# D1H.pdf register map
Vendor: Allwinner; Series: D1H.pdf; File version: 0.1
CPU: XuanTie C906 RISC-V CPU 0, little endian, MPU, FPU, double-precision FPU, 0 interrupt priority bits
Registers are 32-bit, read-write, reset 0x0 unless marked. A register's access mark holds for its fields unless they carry their own. Offsets are from the block's base; [hi:lo] are bit positions; lines under a group give offsets from that group; {n}, {i} and the like mark numbered series; 'fields as' and 'values as' point back to an identical list; <NAME> marks a mode.

## Audio_Codec (part 2 of 5)
Base 0x02030000
0x00 AUDIO CODEC group
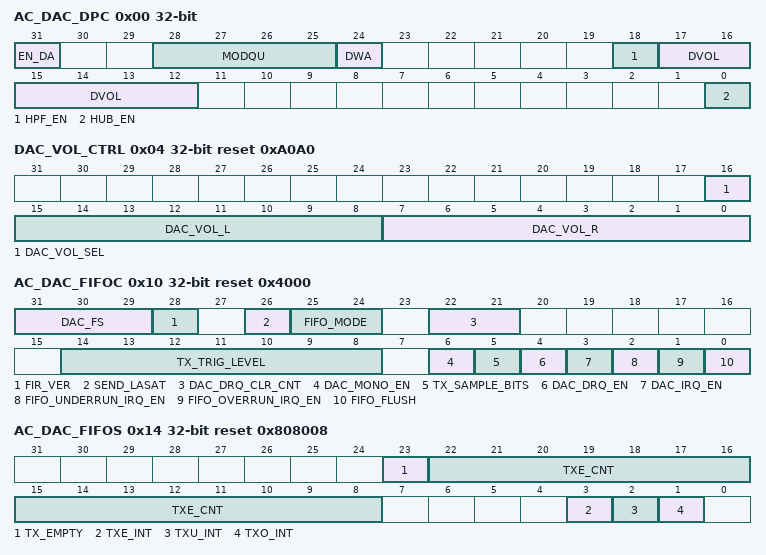
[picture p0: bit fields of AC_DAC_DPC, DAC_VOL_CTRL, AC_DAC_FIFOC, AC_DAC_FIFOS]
  0x00 AC_DAC_DPC — DAC Digital Part Control Register
    [31] EN_DA — DAC Digital Part Enable 0: Disabled 1: Enabled
      0=Disabled; 1=Enabled
    [28:25] MODQU — Internal DAC Quantization Levels Levels = [7*(21 + MODQU[3:0])]/128 Default levels = 7*21/128 = 1.15
    [24] DWA — DWA Function Disable 0: Enabled 1: Disabled
      0=Enabled; 1=Disabled
    [18] HPF_EN — High Pass Filter Enable 0: Disabled 1: Enabled
      0=Disabled; 1=Enabled
    [17:12] DVOL — Digital volume control: DVC, ATT = DVC[5:0]*(-1.16 dB) 64 steps, -1.16 dB/step
    [0] HUB_EN — Audio Hub Enable The bit takes effect only when the EN_DA is set to 1. System Domain: Audio Codec/I2S0/I2S1/I2S2/OWA TXFIFO Hub Enable. 0: Disabled 1: Enabled
      0=Disabled; 1=Enabled
  0x04 DAC_VOL_CTRL reset 0xA0A0 — DAC Volume Control Register
    [16] DAC_VOL_SEL — DAC Volume Control Selection Enable 0: Disabled 1: Enabled
      0=Disabled; 1=Enabled
    [15:8] DAC_VOL_L — DAC left channel volume (-119.25 dB to 71.25 dB, 0.75 dB/Step) 0x00: Mute 0x01: -119.25 dB ... 0x9F = -0.75 dB 0xA0 = 0 dB 0xA1 = 0.75 dB ... 0xFF = 71.25 dB
      0=Mute; 1=_minus_119_point_25_dB (-119.25 dB ... 0x9F = -0.75 dB 0xA0 = 0 dB 0xA1 = 0.75 dB ... 0xFF = 71.25 dB)
    [7:0] DAC_VOL_R — DAC right channel volume (-119.25 dB To 71.25 dB, 0.75 dB/Step) 0x00: Mute 0x01: -119.25 dB ... 0x9F = -0.75 dB 0xA0 = 0 dB 0xA1 = 0.75 dB ... 0xFF = 71.25 dB
      values as DAC_VOL_L
  0x10 AC_DAC_FIFOC reset 0x4000 — DAC FIFO Control Register
    [31:29] DAC_FS — Sample Rate of DAC 000: 48 kHz 010: 24 kHz 100: 12 kHz 110: 192 kHz 001: 32 kHz 011: 16 kHz 101: 8 kHz 111: 96 kHz 44.1 kHz/22.05 kHz/11.025 kHz can be supported by Audio PLL Configure Bit
      0=_48_kHz; 2=_24_kHz; 4=_12_kHz; 6=_192_kHz; 1=_32_kHz; 3=_16_kHz; 5=_8_kHz; 7=96 kHz 44.1 kHz/22.05 kHz/11.025 kHz can be supported by Audio PLL Configure Bit
    [28] FIR_VER — FIR Version 0: 64-Tap FIR 1: 32-Tap FIR
      0=_64_minus_Tap (64-Tap FIR); 1=_32_minus_Tap (32-Tap FIR)
    [26] SEND_LASAT — Audio sample select when TX FIFO underrun 0: Sending zero 1: Sending the last audio sample
      0=Sending_zero; 1=Sending the last audio sample
    [25:24] FIFO_MODE — For 20-bit transmitted audio sample: 00/10: FIFO_I[19:0] = {TXDATA[31:12]} 01/11: FIFO_I[19:0] = {TXDATA[19:0]} For 16-bit transmitted audio sample: 00/10: FIFO_I[19:0] = {TXDATA[31:16], 4’b0} 01/11: FIFO_I[19:0] = {TXDATA[15:0], 4’b0}
    [22:21] DAC_DRQ_CLR_CNT — When TX FIFO available room is less than or equal N, the DRQ request will be de-asserted. N is defined here: 00: IRQ/DRQ de-asserted when WLEVEL > TXTL 01: 4 10: 8 11: 16
      0=IRQ_slash_DRQ (IRQ/DRQ de-asserted when WLEVEL > TXTL); 1=_4; 2=_8; 3=_16
    [14:8] TX_TRIG_LEVEL — TX FIFO Empty Trigger Level (TXTL[12:0]) Interrupt and DMA request trigger level for TX FIFO normal condition. IRQ/DRQ generated when WLEVEL ≤ TXTL
    [6] DAC_MONO_EN — DAC Mono Enable 0: Stereo, 64 levels FIFO 1: Mono, 128 levels FIFO When enabled, L & R channel send the same data.
      0=Stereo, 64 levels FIFO; 1=Mono, 128 levels FIFO When enabled, L & R channel send the same data
    [5] TX_SAMPLE_BITS — Transmitting Audio Sample Resolution 0: 16 bits 1: 20 bits
      0=_16_bits; 1=_20_bits
    [4] DAC_DRQ_EN — DAC FIFO Empty DRQ Enable 0: Disabled 1: Enabled
      0=Disabled; 1=Enabled
    [3] DAC_IRQ_EN — DAC FIFO Empty IRQ Enable 0: Disabled 1: Enabled
      0=Disabled; 1=Enabled
    [2] FIFO_UNDERRUN_IRQ_EN — DAC FIFO Underrun IRQ Enable 0: Disabled 1: Enabled
      0=Disabled; 1=Enabled
    [1] FIFO_OVERRUN_IRQ_EN — DAC FIFO Overrun IRQ Enable 0: Disabled 1: Enabled
      0=Disabled; 1=Enabled
    [0] FIFO_FLUSH write-clears — DAC FIFO Flush Write ‘1’ to flush TX FIFO, self clear to ‘0’
  0x14 AC_DAC_FIFOS reset 0x808008 — DAC FIFO Status Register
    [23] TX_EMPTY ro — TX FIFO Empty 0: No room for new sample in TX FIFO 1: More than one room for new sample in TX FIFO (>= 1 word)
      0=No room for new sample in TX FIFO; 1=More than one room for new sample in TX FIFO (>= 1 word)
    [22:8] TXE_CNT ro — TX FIFO Empty Space Word Counter
    [3] TXE_INT write-1-clears — TX FIFO Empty Pending Interrupt 0: No Pending IRQ 1: FIFO Empty Pending Interrupt Write ‘1’ to clear this interrupt or automatically clear if the interrupt condition fails.
      0=No Pending IRQ; 1=FIFO (FIFO Empty Pending Interrupt Write ‘1’ to clear this interrupt or automatically clear if the interrupt condition fails.)
    [2] TXU_INT write-1-clears — TX FIFO Underrun Pending Interrupt 0: No Pending Interrupt 1: FIFO Underrun Pending Interrupt Write ‘1’ to clear this interrupt
      0=No Pending Interrupt; 1=FIFO (FIFO Underrun Pending Interrupt Write ‘1’ to clear this interrupt)
    [1] TXO_INT write-1-clears — TX FIFO Overrun Pending Interrupt 0: No Pending Interrupt 1: FIFO Overrun Pending Interrupt Write ‘1’ to clear this interrupt
      0=No Pending Interrupt; 1=FIFO (FIFO Overrun Pending Interrupt Write ‘1’ to clear this interrupt)
  0x20 AC_DAC_TXDATA — DAC TX DATA Register
    [31:0] TX_DATA wo — Write the transmitting left and right channel sample data to this register one by one. Write the left channel sample data first and then the right channel sample.
  0x24 AC_DAC_CNT — DAC TX FIFO Counter Register
    [31:0] TX_CNT — TX Sample Counter The audio sample number of sending into TXFIFO. When one sample is put into TXFIFO by DMA or by host IO, the TX sample counter register increases by one. The TX sample counter register can be set to any initial valve at any time. After being updated by the initial value, the counter register should count from this initial value.
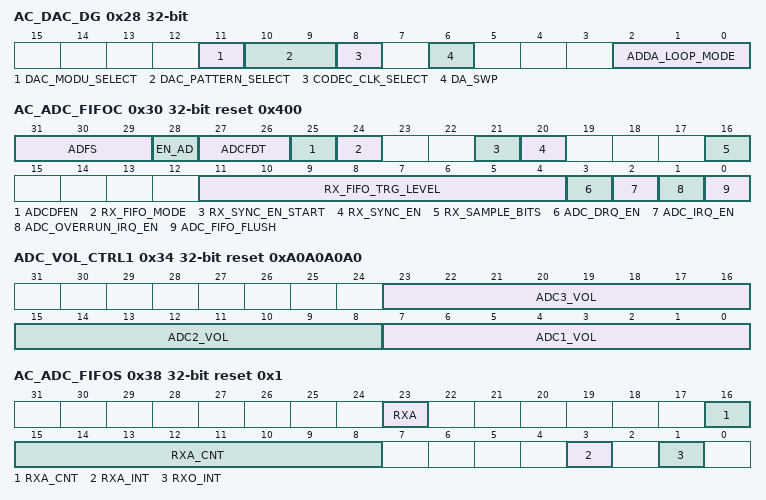
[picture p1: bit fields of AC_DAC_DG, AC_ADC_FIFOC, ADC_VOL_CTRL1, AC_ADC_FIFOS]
  0x28 AC_DAC_DG — DAC Debug Register
    [11] DAC_MODU_SELECT — DAC Modulator Debug 0: DAC Modulator Normal Mode 1: DAC Modulator Debug Mode
      0=DAC Modulator Normal Mode; 1=DAC Modulator Debug Mode
    [10:9] DAC_PATTERN_SELECT — DAC Pattern Select 00: Normal (Audio sample from TX FIFO) 01: -6 dB Sin wave 10: -60 dB Sin wave 11: Silent wave
      0=Normal (Audio sample from TX FIFO); 1=_minus_6_dB (-6 dB Sin wave); 2=_minus_60_dB (-60 dB Sin wave); 3=Silent wave
    [8] CODEC_CLK_SELECT — CODEC Clock Source Select 0: CODEC clock from PLL 1: CODEC clock from OSC (for Debug)
      0=CODEC_clock_from_PLL; 1=CODEC clock from OSC (for Debug)
    [6] DA_SWP — DAC Output Channel Swap Enable 0: Disabled 1: Enabled
      0=Disabled; 1=Enabled
    [2:0] ADDA_LOOP_MODE — ADDA Loop Mode Select 000: Disabled 001: ADDA LOOP MODE DACL/DACR is connected to ADC1/ADC2 010: ADDA LOOP MODE DACL/DACR is connected to ADC3 Others: Reserved
  0x30 AC_ADC_FIFOC reset 0x400 — ADC FIFO Control Register
    [31:29] ADFS — Sample Rate of ADC 000: 48 kHz 010: 24 kHz 100: 12 kHz 110: Reserved 001: 32 kHz 011: 16 kHz 101: 8 kHz 111: Reserved 44.1 kHz/22.05 kHz/11.025 kHz can be supported by Audio PLL Configure Bit.
      0=_48_kHz; 2=_24_kHz; 4=_12_kHz; 1=_32_kHz; 3=_16_kHz; 5=_8_kHz
    [28] EN_AD — ADC Digital Part Enable 0: Disabled 1: Enabled
      0=Disabled; 1=Enabled
    [27:26] ADCFDT — ADC FIFO delay time for writing data after EN_AD 00: 5 ms 01: 10 ms 10: 20 ms 11: 30 ms
      0=_5_ms; 1=_10_ms; 2=_20_ms; 3=_30_ms
    [25] ADCDFEN — ADC FIFO delay function for writing data after EN_AD 0: Disabled 1: Enabled
      0=Disabled; 1=Enabled
    [24] RX_FIFO_MODE — RX FIFO Output Mode (Mode 0, 1) 0: Expanding ‘0’ at LSB of TX FIFO register 1: Expanding received sample sign bit at MSB of TX FIFO register For 20-bit received audio sample: Mode 0: RXDATA[31:0] = {FIFO_O[19:0], 12’h0} Mode 1: RXDATA[31:0] = {12{FIFO_O[19]}, FIFO_O[19:0]} For 16-bit received audio sample: Mode 0: RXDATA[31:0] = {FIFO_O[19:4], 16’h0} Mode 1: RXDATA[31:0] = {16{FIFO_O[19]}, FIFO_O[19:4]}
      0=Expanding__quote_0_quote_ (Expanding ‘0’ at LSB of TX FIFO register); 1=Expanding received sample sign bit at MSB of TX FIFO register For 20-bit received audio sample: Mode 0: RXDATA[31:0] = {FIFO_O[19:0], 12’h0} Mode 1: RXDATA[31:0] = {12{FIFO_O[19]}, FIFO_O[19:0]} For 16-bit received audio sample: Mode 0: RXDATA[31:0] = {FIFO_O[19:4], 16’h0} Mode 1: RXDATA[31:0] = {16{FIFO_O[19]}, FIFO_O[19:4]}
    [21] RX_SYNC_EN_START — The bit takes effect only when RX_SYNC_EN is set to 1. System Domain: Audio codec/I2S0/I2S1/I2S2/DMIC Synchronize Enable Start. 0: Disabled 1: Enabled
      0=Disabled; 1=Enabled
    [20] RX_SYNC_EN — Audiocodec RX Synchronize Enable 0: Disabled 1: Enabled
      0=Disabled; 1=Enabled
    [16] RX_SAMPLE_BITS — Receiving Audio Sample Resolution 0: 16 bits 1: 20 bits
      0=_16_bits; 1=_20_bits
    [11:4] RX_FIFO_TRG_LEVEL — RX FIFO Trigger Level (RXTL[5:0]) Interrupt and DMA request trigger level for RX FIFO normal condition IRQ/DRQ generated when WLEVEL > RXTL[5:0]
    [3] ADC_DRQ_EN — ADC FIFO Data Available DRQ Enable 0: Disabled 1: Enabled
      0=Disabled; 1=Enabled
    [2] ADC_IRQ_EN — ADC FIFO Data Available IRQ Enable 0: Disabled 1: Enabled
      0=Disabled; 1=Enabled
    [1] ADC_OVERRUN_IRQ_EN — ADC FIFO Overrun IRQ Enable 0: Disabled 1: Enabled
      0=Disabled; 1=Enabled
    [0] ADC_FIFO_FLUSH write-clears — ADC FIFO Flush Write ‘1’ to flush TX FIFO, self clear to ‘0’.
  0x34 ADC_VOL_CTRL1 reset 0xA0A0A0A0 — ADC Volume Control1 Register
    [all] fields
      0=Mute; 1=_minus_119_point_25_dB (-119.25 dB ...); 159=_minus_0_point_75_dB (-0.75 dB); 160=_0_dB; 161=_0_point_75_dB (0.75 dB ...); 255=_71_point_25_dB (71.25 dB)
    [23:16] ADC3_VOL — ADC3 channel volume (-119.25 dB To 71.25 dB, 0.75 dB/Step) 0x00: Mute 0x01: -119.25 dB ... 0x9F: -0.75 dB 0xA0: 0 dB 0xA1: 0.75 dB ... 0xFF: 71.25 dB
    [15:8] ADC2_VOL — ADC2 channel volume (-119.25 dB To 71.25 dB, 0.75 dB/Step) 0x00: Mute 0x01: -119.25 dB ... 0x9F: -0.75 dB 0xA0: 0 dB 0xA1: 0.75 dB ... 0xFF: 71.25 dB
    [7:0] ADC1_VOL — ADC1 channel volume (-119.25 dB To 71.25 dB, 0.75 dB/Step) 0x00: Mute 0x01: -119.25 dB ... 0x9F: -0.75 dB 0xA0: 0 dB 0xA1: 0.75 dB ... 0xFF: 71.25 dB
  0x38 AC_ADC_FIFOS reset 0x1 — ADC FIFO Status Register
    [23] RXA ro — RX FIFO Available 0: No available data in RX FIFO 1: More than one sample in RX FIFO (>= 1 word)
      0=No available data in RX FIFO; 1=More than one sample in RX FIFO (>= 1 word)
    [16:8] RXA_CNT ro — RX FIFO Available Sample Word Counter
    [3] RXA_INT write-1-clears — RX FIFO Data Available Pending Interrupt 0: No Pending IRQ 1: Data Available Pending IRQ Write ‘1’ to clear this interrupt or automatic clear if the interrupt condition fails.
      0=No Pending IRQ; 1=Data Available Pending IRQ Write ‘1’ to clear this interrupt or automatic clear if the interrupt condition fails
    [1] RXO_INT write-1-clears — RX FIFO Overrun Pending Interrupt 0: No Pending IRQ 1: FIFO Overrun Pending IRQ Write ‘1’ to clear this interrupt.
      0=No Pending IRQ; 1=FIFO (FIFO Overrun Pending IRQ Write ‘1’ to clear this interrupt.)
  0x40 AC_ADC_RXDATA — ADC RX Data Register
    [31:0] RX_DATA ro — RX Sample The host can get one sample by reading this register. The left channel sample data comes first and then the right channel sample.
  0x44 AC_ADC_CNT — ADC RX Counter Register
    [31:0] RX_CNT — RX Sample Counter The audio sample number of writing into RXFIFO. When one sample is written by Digital Audio Engine, the RX sample counter register increases by one. The RX sample counter register can be set to any initial valve at any time. After being updated by the initial value, the counter register should count from this initial value.
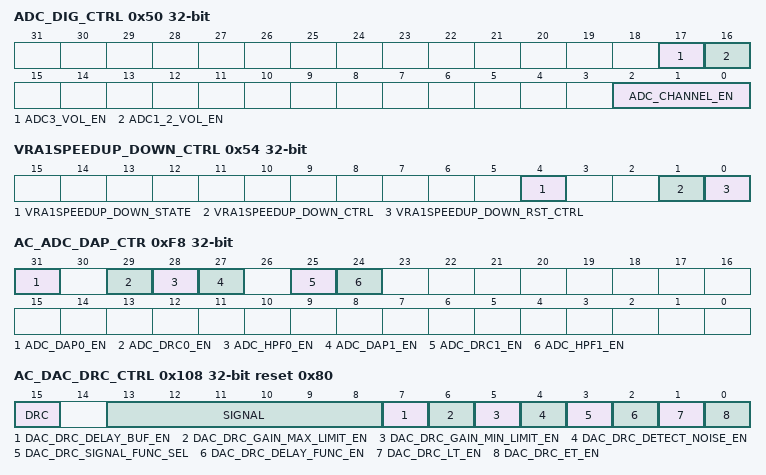
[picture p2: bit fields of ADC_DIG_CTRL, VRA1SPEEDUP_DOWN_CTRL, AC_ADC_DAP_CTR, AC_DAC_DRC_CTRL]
  0x50 ADC_DIG_CTRL — ADC Digtial Control Register
    [17] ADC3_VOL_EN — ADC3 Volume Control Enable 0: Disabled 1: Enabled
      0=Disabled; 1=Enabled
    [16] ADC1_2_VOL_EN — ADC1/2 Volume Control Enable 0: Disabled 1: Enabled
      0=Disabled; 1=Enabled
    [2:0] ADC_CHANNEL_EN — Bit 3: ADC4 enabled Bit 2: ADC3 enabled Bit 1: ADC2 enabled Bit 0: ADC1 enabled
  0x54 VRA1SPEEDUP_DOWN_CTRL
    [4] VRA1SPEEDUP_DOWN_STATE ro — Only if VAR1SPEEDUP_DOWN_Further_CTRL (0x310[22]) is set 0, VAR1Speedup Down State is valid. 0: VAR1Speedup_Down does not work. 1: VAR1Speedup_Down works.
      0=VAR1Speedup_Down does not work; 1=VAR1Speedup_Down_works
    [1] VRA1SPEEDUP_DOWN_CTRL — VAR1Speedup Down Manual Control Enable 0: Disabled. VAR1Speedup Down converts to 1 after the bus rst releases 32 ms. 1: Enabled. VAR1Speedup Down converts to 1 immediately.
      0=Disabled. VAR1Speedup Down converts to 1 after the bus rst releases 32 ms.; 1=Enabled. VAR1Speedup Down converts to 1 immediately.
    [0] VRA1SPEEDUP_DOWN_RST_CTRL — VAR1Speedup Down RST Manual Control Enable 0: Disabled. VAR1Speedup Down converts to 1 after the bus rst releases 32 ms. 1: Enabled. VAR1Speedup Down reset 0 immediately.
      0=Disabled. VAR1Speedup Down converts to 1 after the bus rst releases 32 ms.; 1=Enabled. VAR1Speedup Down reset 0 immediately.
  0xF8 AC_ADC_DAP_CTR — ADC DAP Control Register
    [31] ADC_DAP0_EN — (control the DAP of ADC1/2) DAP for ADC enable 0: Bypassed 1: Enabled
      0=Bypassed; 1=Enabled
    [29] ADC_DRC0_EN — ADC DRC0 enable control 0: Disabled 1: Enabled
      0=Disabled; 1=Enabled
    [28] ADC_HPF0_EN — ADC HPF0 enable control 0: Disabled 1: Enabled
      0=Disabled; 1=Enabled
    [27] ADC_DAP1_EN — (control the DAP of ADC3) ADC DAP1 enable control
    [25] ADC_DRC1_EN — ADC DRC1 enable control 0: Disabled 1: Enabled
      0=Disabled; 1=Enabled
    [24] ADC_HPF1_EN — ADC HPF1 enable control 0: Disabled 1: Enabled
      0=Disabled; 1=Enabled
  0x100 AC_DAC_DRC_HHPFC reset 0xFF — DAC DRC High HPF Coef Register
    [10:0] HPF — coefficient setting and the data is 3.24 format.
  0x104 AC_DAC_DRC_LHPFC reset 0xFAC1 — DAC DRC Low HPF Coef Register
    [15:0] HPF — coefficient setting and the data is 3.24 format.
  0x108 AC_DAC_DRC_CTRL reset 0x80 — DAC DRC Control Register
    [15] DRC ro — delay buffer data output state when The DRC delay function is enabled and the DRC function is disabled. After disabling the DRC function and this bit goes to 0, write the DRC delay function bit to 0. 0: Not completed 1: Completed
      0=Not_completed; 1=Completed
    [13:8] SIGNAL — Signal delay time setting 6'h00: (8x1) fs 6'h01: (8x2) fs 6'h02: (8x3) fs ---------------------------------------- 6'h2e: (8*47) fs 6'h2f: (8*48) fs 6'h30 -- 6'h3f: (8*48) fs Delay time = 8*(n + 1) fs, n<6'h30; When the delay function is disabled, the signal delay time is unused.
    [7] DAC_DRC_DELAY_BUF_EN — The delay buffer use or not when the DRC is disabled and the DRC buffer data output completely. 0: Do not use the buffer. 1: Use the buffer.
      0=Do_not_use_the_buffer; 1=Use_the_buffer
    [6] DAC_DRC_GAIN_MAX_LIMIT_EN — DRC gain max limit enable 0: Disabled 1: Enabled
      0=Disabled; 1=Enabled
    [5] DAC_DRC_GAIN_MIN_LIMIT_EN — DRC gain min limit enable When this function is enabled, it will overwrite the noise detect function. 0: Disabled 1: Enabled
      0=Disabled; 1=Enabled
    [4] DAC_DRC_DETECT_NOISE_EN — Control the DRC to detect noise when ET is enabled. 0: Disabled 1: Enabled
      0=Disabled; 1=Enabled
    [3] DAC_DRC_SIGNAL_FUNC_SEL — Signal function select 0: RMS filter 1: Peak filter When the signal function selects the Peak filter, the RMS parameter is unused. (AC_DRC_LRMSHAT, AC_DRC_LRMSLAT, AC_DRC_LRMSHAT, AC_DRC_LRMSLAT) When the signal function selects the RMS filter, the Peak filter parameter is unused. (AC_DRC_LPFHAT, AC_DRC_LPFLAT, AC_DRC_RPFHAT, AC_DRC_RPFLAT, AC_DRC_LPFHRT, AC_DRC_LPFLRT, AC_DRC_RPFHRT, and AC_DRC_RPFLRT)
      0=RMS (RMS filter); 1=Peak filter When the signal function selects the Peak filter, the RMS parameter is unused. (AC_DRC_LRMSHAT, AC_DRC_LRMSLAT, AC_DRC_LRMSHAT, AC_DRC_LRMSLAT) When the signal function selects the RMS filter, the Peak filter parameter is unused. (AC_DRC_LPFHAT, AC_DRC_LPFLAT, AC_DRC_RPFHAT, AC_DRC_RPFLAT, AC_DRC_LPFHRT, AC_DRC_LPFLRT, AC_DRC_RPFHRT, and AC_DRC_RPFLRT)
    [2] DAC_DRC_DELAY_FUNC_EN — Delay function enable 0: Disabled 1: Enabled When the bit is disabled, the signal delay time is unused.
      0=Disabled; 1=Enabled When the bit is disabled, the signal delay time is unused
    [1] DAC_DRC_LT_EN — DRC LT enable 0: Disabled 1: Enabled When the bit is disabled, Kl and OPL parameter is unused.
      0=Disabled; 1=Enabled When the bit is disabled, Kl and OPL parameter is unused
    [0] DAC_DRC_ET_EN — DRC ET enable 0: Disabled 1: Enabled When the bit is disabled, Ke and OPE parameter is unused.
      0=Disabled; 1=Enabled When the bit is disabled, Ke and OPE parameter is unused
  0x10C AC_DAC_DRC_LPFHAT reset 0xB — DAC DRC Left Peak Filter High Attack Time Coef Register
    [10:0] DAC_DRC_LPFHAT — The left peak filter attack time parameter setting, which is determined by the equation that AT = 1-exp (-2.2Ts/ta). The format is 3.24. (The default value is 1 ms)
  0x110 AC_DAC_DRC_LPFLAT reset 0x77BF — DAC DRC Left Peak Filter Low Attack Time Coef Register
    [15:0] DAC_DRC_LPFLAT — The left peak filter attack time parameter setting, which is determined by the equation that AT = 1-exp (-2.2Ts/ta). The format is 3.24. (The default value is 1 ms)
  0x114 AC_DAC_DRC_RPFHAT reset 0xB — DAC DRC Right Peak Filter High Attack Time Coef Register
    [15:0] DAC_DRC_RPFHAT — The right peak filter attack time parameter setting, which is determined by the equation that AT = 1-exp (-2.2Ts/ta). The format is 3.24. (The default value is 1 ms)
  0x118 AC_DAC_DRC_RPFLAT reset 0x77BF — DAC DRC Peak Filter Low Attack Time Coef Register
    [15:0] DAC_DRC_RPFLAT — The left peak filter attack time parameter setting, which is determined by the equation that AT = 1-exp (-2.2Ts/ta). The format is 3.24. (The default value is 1 ms)
  0x11C AC_DAC_DRC_LPFHRT reset 0xFF — DAC DRC Left Peak Filter High Release Time Coef Register
    [10:0] DAC_DRC_LPFHRT — The left peak filter release time parameter setting, which is determined by the equation that RT = exp (-2.2Ts/tr). The format is 3.24. (The default value is 100 ms)
  0x120 AC_DAC_DRC_LPFLRT reset 0xE1F8 — DAC DRC Left Peak Filter Low Release Time Coef Register
    [15:0] DAC_DRC_LPFLRT — The left peak filter release time parameter setting, which is determined by the equation that RT = exp (-2.2Ts/tr). The format is 3.24. (The default value is 100 ms)
  0x124 AC_DAC_DRC_RPFHRT reset 0xFF — DAC DRC Right Peak filter High Release Time Coef Register
    [15:0] DAC_DRC_RPFHRT — The right peak filter release time parameter setting, which is determined by the equation that RT = exp (-2.2Ts/tr). The format is 3.24. (The default value is 100 ms)
  0x128 AC_DAC_DRC_RPFLRT reset 0xE1F8 — DAC DRC Right Peak filter Low Release Time Coef Register
    [15:0] DAC_DRC_RPFLRT — The right peak filter release time parameter setting, which is determined by the equation that AT = exp(-2.2Ts/tr). The format is 3.24. (The default value is 100 ms)
  0x12C AC_DAC_DRC_LRMSHAT reset 0x1 — DAC DRC Left RMS Filter High Coef Register
    [10:0] DAC_DRC_LRMSHAT — The left RMS filter average time parameter setting, which is determined by the equation that AT = 1-exp (-2.2Ts/tav). The format is 3.24. (The default value is 10 ms)
  0x130 AC_DAC_DRC_LRMSLAT reset 0x2BAF — DAC DRC Left RMS Filter Low Coef Register
    [15:0] DAC_DRC_LRMSLAT — The left RMS filter average time parameter setting, which is determined by the equation that AT = 1-exp (-2.2Ts/tav). The format is 3.24. (The default value is 10 ms)
  0x134 AC_DAC_DRC_RRMSHAT reset 0x2BAF — DAC DRC Right RMS Filter High Coef Register
    [15:0] DAC_DRC_RRMSHAT — The right RMS filter average time parameter setting, which is determined by the equation that AT = 1-exp (-2.2Ts/tav). The format is 3.24. (The default value is 10 ms)
  0x138 AC_DAC_DRC_RRMSLAT reset 0x2BAF — DAC DRC Right RMS Filter Low Coef Register
    [15:0] DAC_DRC_RRMSLAT — The right RMS filter average time parameter setting, which is determined by the equation that AT = 1-exp (-2.2Ts/tav). The format is 3.24. (The default value is 10 ms)
  0x13C AC_DAC_DRC_HCT reset 0x6A4 — DAC DRC Compressor Threshold High Setting Register
    [15:0] DAC_DRC_HCT — The compressor threshold setting, which is set by the equation that CTin = -CT/6.0206. The format is 8.24. (The default value is - 40 dB)
  0x140 AC_DAC_DRC_LCT reset 0xD3C0 — DAC DRC Compressor Slope High Setting Register
    [15:0] DAC_DRC_LCT — The compressor threshold setting, which is set by the equation that CTin = -CT/6.0206. The format is 8.24. (The default value is - 40 dB)
  0x144 AC_DAC_DRC_HKC reset 0x80 — DAC DRC Compressor Slope High Setting Register
    [15:0] DAC_DRC_HKC — The slope of the compressor, which is determined by the equation that Kc = 1/R. R is the ratio of the compressor, which is always an integer. The format is 8.24. (The default value is 2:1)
  0x148 AC_DAC_DRC_LKC — DAC DRC Compressor Slope Low Setting Register
    [15:0] DAC_DRC_LKC — The slope of the compressor, which is determined by the equation that Kc = 1/R. R is the ratio of the compressor, which is always an integer. The format is 8.24. (The default value is 2:1)
  0x14C AC_DAC_DRC_HOPC reset 0xF95B — DAC DRC Compressor High Output at Compressor Threshold Register
    [15:0] DAC_DRC_HOPC — The output of the compressor, which is determined by the equation -OPC/6.0206. The format is 8.24 (The default value is -40 dB)
  0x150 AC_DAC_DRC_LOPC reset 0x2C3F — DAC DRC Compressor Low Output at Compressor Threshold Register
    [15:0] DAC_DRC_LOPC — The output of the compressor, which is determined by the equation OPC/6.0206. The format is 8.24. (The default value is -40 dB)
  0x154 AC_DAC_DRC_HLT reset 0x1A9 — DAC DRC Limiter Threshold High Setting Register
    [15:0] DAC_DRC_HLT — The limiter threshold setting, which is set by the equation that LTin = -LT/6.0206, The format is 8.24. (The default value is -10 dB)
  0x158 AC_DAC_DRC_LLT reset 0x34F0 — DAC DRC Limiter Threshold Low Setting Register
    [15:0] DAC_DRC_LLT — The limiter threshold setting, which is set by the equation that LTin = -LT/6.0206. The format is 8.24. (The default value is -10 dB)
  0x15C AC_DAC_DRC_HKl reset 0x5 — DAC DRC Limiter Slope High Setting Register
    [15:0] DAC_DRC_HKL — The slope of the limiter which is determined by the equation that Kl = 1/R. R is the ratio of the limiter, which is always an integer. The format is 8.24. (The default value is <50:1>)
  0x160 AC_DAC_DRC_LKl reset 0x1EB8 — DAC DRC Limiter Slope Low Setting Register
    [15:0] DAC_DRC_LKL — The slope of the limiter, which is determined by the equation that Kl = 1/R. R is the ratio of the limiter, which is always an integer. The format is 8.24. (The default value is <50:1>)
  0x164 AC_DAC_DRC_HOPL reset 0xFBD8 — DAC DRC Limiter High Output at Limiter Threshold
    [15:0] DAC_DRC_HOPL — The output of the limiter, which is determined by equation OPT/6.0206. The format is 8.24. (The default value is -25 dB)
  0x168 AC_DAC_DRC_LOPL reset 0xFBA7 — DAC DRC Limiter Low Output at Limiter Threshold
    [15:0] DAC_DRC_LOPL — The output of the limiter, which is determined by equation OPT/6.0206. The format is 8.24. (The default value is -25 dB)
  0x16C AC_DAC_DRC_HET reset 0xBA0 — DAC DRC Expander Threshold High Setting Register
    [15:0] DAC_DRC_HET — The expander threshold setting, which is set by the equation that ETin = -ET/6.0206. The format is 8.24. (The default value is -70 dB)
  0x170 AC_DAC_DRC_LET reset 0x7291 — DAC DRC Expander Threshold Low Setting Register
    [15:0] DAC_DRC_LET — The expander threshold setting, which is set by the equation that ETin = -ET/6.0206. The format is 8.24. (The default value is -70 dB)
  0x174 AC_DAC_DRC_HKE reset 0x500 — DAC DRC Expander Slope High Setting Register
    [13:0] DAC_DRC_HKE — The slope of the expander, which is determined by the equation that Ke = 1/R. R is the ratio of the expander, which is always an integer and the ke must larger than 50. The format is 8.24. (The default value is <1:5>)
  0x178 AC_DAC_DRC_LKE — DAC DRC Expander Slope Low Setting Register
    [15:0] DAC_DRC_LKE — The slope of the expander, which is determined by the equation that Ke = 1/R. R is the ratio of the expander, which is always an integer and the ke must larger than 50. The format is 8.24. (The default value is <1:5>)
  0x17C AC_DAC_DRC_HOPE reset 0xF45F — DAC DRC Expander High Output at Expander Threshold
    [15:0] DAC_DRC_HOPE — The output of the expander, which is determined by equation OPE/6.0206. The format is 8.24. (The default value is -70 dB)
  0x180 AC_DAC_DRC_LOPE reset 0x8D6E — DAC DRC Expander Low Output at Expander Threshold
    [15:0] DAC_DRC_LOPE — The output of the expander which is determined by equation OPE/6.0206. The format is 8.24. (The default value is -70 dB)
  0x184 AC_DAC_DRC_HKN reset 0x100 — DAC DRC Linear Slope High Setting Register
    [15:0] DAC_DRC_HKN — The slope of the linear, which is determined by the equation that Kn = 1/R. R is the ratio of the linear, which is always an integer. The format is 8.24. (The default value is <1:1>)
  0x188 AC_DAC_DRC_LKN — DAC DRC Linear Slope Low Setting Register
    [15:0] DAC_DRC_LKN — The slope of the linear, which is determined by the equation that Kn = 1/R. R is the ratio of the linear, which is always an integer. The format is 8.24. (The default value is <1:1>)
  0x18C AC_DAC_DRC_SFHAT reset 0x2 — DAC DRC Smooth filter Gain High Attack Time Coef Register
    [10:0] DAC_DRC_SFHAT — The smooth filter attack time parameter setting, which is determined by the equation that AT = 1-exp (-2.2Ts/tr). The format is 3.24. (The default value is 5 ms)
  0x190 AC_DAC_DRC_SFLAT reset 0x5600 — DAC DRC Smooth filter Gain Low Attack Time Coef Register
    [15:0] DAC_DRC_SFLAT — The smooth filter attack time parameter setting, which is determined by the equation that AT = 1-exp (-2.2Ts/tr). The format is 3.24. (The default value is 5 ms)
  0x194 AC_DAC_DRC_SFHRT — DAC DRC Smooth filter Gain High Release Time Coef Register
    [10:0] DAC_DRC_SFHRT — The gain smooth filter release time parameter setting, which is determined by the equation that RT = 1-exp (-2.2Ts/tr). The format is 3.24. (The default value is 200 ms)
  0x198 AC_DAC_DRC_SFLRT reset 0xF04 — DAC DRC Smooth filter Gain Low Release Time Coef Register
    [15:0] DAC_DRC_SFLRT — The gain smooth filter release time parameter setting, which is determined by the equation that RT = 1-exp (-2.2Ts/tr). The format is 3.24. (The default value is 200 ms)
  0x19C AC_DAC_DRC_MXGHS reset 0xFE56 — DAC DRC MAX Gain High Setting Register
    [15:0] DAC_DRC_MXGHS — The max gain setting, which is determined by equation MXG =MXG/6.0206. The format is 8.24 and must -20 dB < MXG < 30 dB (The default value is -10 dB)
  0x1A0 AC_DAC_DRC_MXGLS reset 0xCB0F — DAC DRC MAX Gain Low Setting Register
    [15:0] DAC_DRC_MXGLS — The max gain setting, which is determined by equation MXG =MXG/6.0206. The format is 8.24 and must -20 dB < MXG < 30 dB (The default value is -10 dB)
  0x1A4 AC_DAC_DRC_MNGHS reset 0xF95B — DAC DRC MIN Gain High Setting Register
    [15:0] DAC_DRC_MNGHS — The min gain setting, which is determined by equation MXG =MXG/6.0206. The format is 8.24 and must -60 dB ≤ MNG ≤ -40 dB (The default value is -40 dB)
  0x1A8 AC_DAC_DRC_MNGLS reset 0x2C3F — DAC DRC MIN Gain Low Setting Register
    [15:0] DAC_DRC_MNGLS — The min gain setting, which is determined by equation MXG =MNG/6.0206. The format is 8.24 and must -60 dB ≤ MNG ≤ -40 dB (The default value is -40 dB)
  0x1AC AC_DAC_DRC_EPSHC — DAC DRC Expander Smooth Time High Coef Register
    [10:0] DAC_DRC_EPSHC — The gain smooth filter release and attack time parameter setting in expander region, which are determined by the equation that RT = 1-exp (-2.2Ts/tr). The format is 3.24. (The default value is 30 ms)
  0x1B0 AC_DAC_DRC_EPSLC reset 0x640C — DAC DRC Expander Smooth Time Low Coef Register
    [15:0] DAC_DRC_EPSLC — The gain smooth filter release and attack time parameter setting in expander region, which are determined by the equation that RT = 1-exp (-2.2Ts/tr). The format is 3.24. (The default value is 30 ms)
  0x1B8 AC_DAC_DRC_HPFHGAIN reset 0x100 — DAC DRC HPF Gain High Coef Register
    [10:0] DAC_DRC_HPFHGAIN — The gain of HPF coefficient. The format is 3.24. (gain = 1)
  0x1BC AC_DAC_DRC_HPFLGAIN — DAC DRC HPF Gain Low Coef Register
    [15:0] DAC_DRC_HPFLGAIN — The gain of HPF coefficient. The format is 3.24. (gain = 1)
  0x200 AC_ADC_DRC_HHPFC reset 0xFF — ADC DRC High HPF Coef Register
    [10:0] ADC_DRC_HHPFC — HPF coefficient setting and the data is 3.24 format.
  0x204 AC_ADC_DRC_LHPFC reset 0xFAC1 — ADC DRC Low HPF Coef Register
    [15:0] HPF — coefficient setting and the data is 3.24 format.
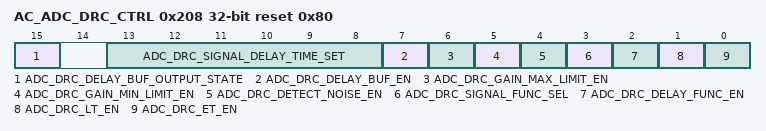
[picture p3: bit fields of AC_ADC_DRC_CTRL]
  0x208 AC_ADC_DRC_CTRL reset 0x80 — ADC DRC Control Register
    [15] ADC_DRC_DELAY_BUF_OUTPUT_STATE ro — DRC delay buffer data output state when The DRC delay function is enabled and the DRC function is disabled. After disabled DRC function and this bit goes to 0, the user should write the DRC delay function bit to 0. 0: Not completed 1: Completed
      0=Not_completed; 1=Completed
    [13:8] ADC_DRC_SIGNAL_DELAY_TIME_SET — Signal delay time setting 6'h00: (8x1) fs 6'h01: (8x2) fs 6'h02: (8x3) fs ---------------------------------------- 6'h2e: (8*47) fs 6'h2f: (8*48) fs 6'h30 -- 6'h3f: (8*48) fs Delay time = 8*(n + 1) fs, n < 6'h30; When the delay function is disabled, the signal delay time is unused.
    [7] ADC_DRC_DELAY_BUF_EN — The delay buffer use or not when the DRC is disabled and the DRC buffer data output completely. 0: Do not use the buffer 1: Use the buffer
      0=Do_not_use_the_buffer; 1=Use_the_buffer
    [6] ADC_DRC_GAIN_MAX_LIMIT_EN — DRC gain max limit enable 0: Disabled 1: Enabled
      0=Disabled; 1=Enabled
    [5] ADC_DRC_GAIN_MIN_LIMIT_EN — DRC gain min limit enable When this fuction is enabled, it will overwrite the noise detect function. 0: Disabled 1: Enabled
      0=Disabled; 1=Enabled
    [4] ADC_DRC_DETECT_NOISE_EN — Control the DRC to detect noise when ET is enabled 0: Disabled 1: Enabled
      0=Disabled; 1=Enabled
    [3] ADC_DRC_SIGNAL_FUNC_SEL — Signal function select 0: RMS filter 1: Peak filter When the signal function selects the Peak filter, the RMS parameter is unused. (AC_DRC_LRMSHAT, AC_DRC_LRMSLAT, AC_DRC_LRMSHAT, and AC_DRC_LRMSLAT) When the signal function selects the RMS filter, the Peak filter parameter is unused. (AC_DRC_LPFHAT, AC_DRC_LPFLAT, AC_DRC_RPFHAT, AC_DRC_RPFLAT, AC_DRC_LPFHRT, AC_DRC_LPFLRT, AC_DRC_RPFHRT, and AC_DRC_RPFLRT)
      0=RMS (RMS filter); 1=Peak filter When the signal function selects the Peak filter, the RMS parameter is unused. (AC_DRC_LRMSHAT, AC_DRC_LRMSLAT, AC_DRC_LRMSHAT, and AC_DRC_LRMSLAT) When the signal function selects the RMS filter, the Peak filter parameter is unused. (AC_DRC_LPFHAT, AC_DRC_LPFLAT, AC_DRC_RPFHAT, AC_DRC_RPFLAT, AC_DRC_LPFHRT, AC_DRC_LPFLRT, AC_DRC_RPFHRT, and AC_DRC_RPFLRT)
    [2] ADC_DRC_DELAY_FUNC_EN — Delay function enable 0: Disabled 1: Enabled When the bit is disabled, the signal delay time is unused.
      values as AUDIO.AC_DAC_DRC_CTRL.DAC_DRC_DELAY_FUNC_EN
    [1] ADC_DRC_LT_EN — DRC LT enable 0: Disabled 1: Enabled When the bit is disabled, Kl and OPL parameter is unused.
      values as AUDIO.AC_DAC_DRC_CTRL.DAC_DRC_LT_EN
    [0] ADC_DRC_ET_EN — DRC ET enable 0: Disabled 1: Enabled When the bit is disabled, Ke and OPE parameter is unused.
      values as AUDIO.AC_DAC_DRC_CTRL.DAC_DRC_ET_EN
  0x20C AC_ADC_DRC_LPFHAT reset 0xB — ADC DRC Left Peak Filter High Attack Time Coef Register
    [10:0] ADC_DRC_LPFHAT — The left peak filter attack time parameter setting, which is determined by the equation that AT = 1-exp (-2.2Ts/ta). The format is 3.24. (The default value is 1 ms)
  0x210 AC_ADC_DRC_LPFLAT reset 0x77BF — ADC DRC Left Peak Filter Low Attack Time Coef Register
    [15:0] ADC_DRC_LPFLAT — The left peak filter attack time parameter setting, which is determined by the equation that AT = 1-exp (-2.2Ts/ta). The format is 3.24. (The default value is 1 ms)
  0x214 AC_ADC_DRC_RPFHAT reset 0xB — ADC DRC Right Peak Filter High Attack Time Coef Register
    [15:0] ADC_DRC_RPFHAT — The right peak filter attack time parameter setting, which is determined by the equation that AT = 1-exp (-2.2Ts/ta). The format is 3.24. (The default value is 1 ms)
  0x218 AC_ADC_DRC_RPFLAT reset 0x77BF — ADC DRC Right Peak Filter Low Attack Time Coef Register
    [15:0] ADC_DRC_RPFLAT — The right peak filter attack time parameter setting, which is determined by the equation that AT = 1-exp (-2.2Ts/ta). The format is 3.24. (The default value is 1 ms)
  0x21C AC_ADC_DRC_LPFHRT reset 0xFF — ADC DRC Left Peak Filter High Release Time Coef Register
    [10:0] ADC_DRC_LPFHRT — The left peak filter release time parameter setting, which is determined by the equation that RT = exp (-2.2Ts/tr). The format is 3.24. (The default value is 100 ms)
  0x220 AC_ADC_DRC_LPFLRT reset 0xE1F8 — ADC DRC Left Peak Filter Low Release Time Coef Register
    [15:0] ADC_DRC_LPFLRT — The left peak filter release time parameter setting, which is determined by the equation that RT = exp (-2.2Ts/tr). The format is 3.24. (The default value is 100 ms)
  0x224 AC_ADC_DRC_RPFHRT reset 0xFF — ADC DRC Right Peak Filter High Release Time Coef Register
    [15:0] ADC_DRC_RPFHRT — The right peak filter release time parameter setting, which is determined by the equation that RT = exp (-2.2Ts/tr). The format is 3.24. (The default value is 100 ms)
  0x228 AC_ADC_DRC_RPFLRT reset 0xE1F8 — ADC DRC Right Peak Filter Low Release Time Coef Register
    [15:0] ADC_DRC_RPFLRT — The right peak filter release time parameter setting, which is determined by the equation that RT = exp (-2.2Ts/tr). The format is 3.24. (The default value is 100 ms)
  0x22C AC_ADC_DRC_LRMSHAT reset 0x1 — ADC DRC Left RMS Filter High Coef Register
    [10:0] ADC_DRC_LRMSHAT — The left RMS filter average time parameter setting, which is determined by the equation that AT = 1-exp (-2.2Ts/tav). The format is 3.24. (The default value is 10 ms)
  0x230 AC_ADC_DRC_LRMSLAT reset 0x2BAF — ADC DRC Left RMS Filter Low Coef Register
    [15:0] ADC_DRC_LRMSLAT — The left RMS filter average time parameter setting, which is determined by the equation that AT = 1-exp (-2.2Ts/tav). The format is 3.24. (The default value is 10 ms)
  0x234 AC_ADC_DRC_RRMSHAT reset 0x1 — ADC DRC Right RMS Filter High Coef Register
    [10:0] ADC_DRC_RRMSHAT — The right RMS filter average time parameter setting, which is determined by the equation that AT = 1-exp (-2.2Ts/tav). The format is 3.24. (The default value is 10 ms)
  0x238 AC_ADC_DRC_RRMSLAT reset 0x2BAF — ADC DRC Right RMS Filter Low Coef Register
    [15:0] ADC_DRC_RRMSLAT — The right RMS filter average time parameter setting, which is determined by the equation that AT = 1-exp (-2.2Ts/tav). The format is 3.24. (The default value is 10 ms)
  0x23C AC_ADC_DRC_HCT reset 0x6A4 — ADC DRC Compressor Threshold High Setting Register
    [15:0] ADC_DRC_HCT — The compressor threshold setting, which is set by the equation that CTin = -CT/6.0206. The format is 8.24. (The default value is - 40 dB)
  0x240 AC_ADC_DRC_LCT reset 0xD3C0 — ADC DRC Compressor Slope High Setting Register
    [15:0] ADC_DRC_LCT — The compressor threshold setting, which is set by the equation that CTin = -CT/6.0206. The format is 8.24. (The default value is - 40 dB)
  0x244 AC_ADC_DRC_HKC reset 0x80 — ADC DRC Compressor Slope High Setting Register
    [15:0] ADC_DRC_HKC — The slope of the compressor which is determined by the equation that Kc = 1/R. R is the ratio of the compressor, which is always an integer. The format is 8.24. (The default value is <2:1>)
  0x248 AC_ADC_DRC_LKC — ADC DRC Compressor Slope Low Setting Register
    [15:0] ADC_DRC_LKC — The slope of the compressor, which is determined by the equation that Kc = 1/R. R is the ratio of the compressor, which is always an integer. The format is 8.24. (The default value is <2:1>)
  0x24C AC_ADC_DRC_HOPC reset 0xF95B — ADC DRC Compressor High Output at Compressor Threshold Register
    [15:0] ADC_DRC_HOPC — The output of the compressor, which is determined by the equation -OPC/6.0206. The format is 8.24. (The default value is -40 dB)
  0x250 AC_ADC_DRC_LOPC reset 0x2C3F — ADC DRC Compressor Low Output at Compressor Threshold Register
    [15:0] ADC_DRC_LOPC — The output of the compressor, which is determined by the equation OPC/6.0206. The format is 8.24. (The default value is -40 dB)
  0x254 AC_ADC_DRC_HLT reset 0x1A9 — ADC DRC Limiter Threshold High Setting Register
    [15:0] ADC_DRC_HLT — The limiter threshold setting, which is set by the equation that LTin = -LT/6.0206. The format is 8.24. (The default value is -10 dB)
  0x258 AC_ADC_DRC_LLT reset 0x34F0 — ADC DRC Limiter Threshold Low Setting Register
    [15:0] ADC_DRC_LLT — The limiter threshold setting, which is set by the equation that LTin = -LT/6.0206. The format is 8.24. (The default value is -10 dB)
  0x25C AC_ADC_DRC_HKl reset 0x5 — ADC DRC Limiter Slope High Setting Register
    [13:0] ADC_DRC_HKL — The slope of the limiter, which is determined by the equation that Kl = 1/R. R is the ratio of the limiter, which is always an integer. The format is 8.24. (The default value is <50:1>)
  0x260 AC_ADC_DRC_LKl reset 0x1EB8 — ADC DRC Limiter Slope Low Setting Register
    [15:0] ADC_DRC_LKL — The slope of the limiter, which is determined by the equation that Kl = 1/R. R is the ratio of the limiter, which is always an integer. The format is 8.24. (The default value is <50:1>)
  0x264 AC_ADC_DRC_HOPL reset 0xFBD8 — ADC DRC Limiter High Output at Limiter Threshold
    [15:0] ADC_DRC_HOPL — The output of the limiter, which is determined by equation OPT/6.0206. The format is 8.24. (The default value is -25 dB)
  0x268 AC_ADC_DRC_LOPL reset 0xFBA7 — ADC DRC Limiter Low Output at Limiter Threshold
    [15:0] ADC_DRC_LOPL — The output of the limiter which is determined by equation OPT/6.0206. The format is 8.24. (The default value is -25 dB)
  0x26C AC_ADC_DRC_HET reset 0xBA0 — ADC DRC Expander Threshold High Setting Register
    [15:0] ADC_DRC_HET — The expander threshold setting, which is set by the equation that ETin = -ET/6.0206, The format is 8.24. (The default value is -70 dB)
  0x270 AC_ADC_DRC_LET reset 0x7291 — ADC DRC Expander Threshold Low Setting Register
    [15:0] ADC_DRC_LET — The expander threshold setting, which is set by the equation that ETin = -ET/6.0206, The format is 8.24. (The default value is -70 dB)
  0x274 AC_ADC_DRC_HKE reset 0x500 — ADC DRC Expander Slope High Setting Register
    [15:0] ADC_DRC_HKE — The slope of the expander, which is determined by the equation that Ke = 1/R. R is the ratio of the expander, which is always an integer and the ke must larger than 50. The format is 8.24. (The default value is <1:5>)
  0x278 AC_ADC_DRC_LKE — ADC DRC Expander Slope Low Setting Register
    [15:0] ADC_DRC_LKE — The slope of the expander, which is determined by the equation that Ke = 1/R. R is the ratio of the expander, which is always an integer and the ke must be larger than 50. The format is 8.24. (The default value is <1:5>)
  0x27C AC_ADC_DRC_HOPE reset 0xF45F — ADC DRC Expander High Output at Expander Threshold
    [15:0] ADC_DRC_HOPE — The output of the expander, which is determined by equation OPE/6.0206. The format is 8.24. (The default value is -70 dB)
  0x280 AC_ADC_DRC_LOPE reset 0x8D6E — ADC DRC Expander Low Output at Expander Threshold
    [15:0] ADC_DRC_LOPE — The output of the expander, which is determined by equation OPE/6.0206. The format is 8.24. (The default value is -70 dB)
  0x284 AC_ADC_DRC_HKN reset 0x100 — ADC DRC Linear Slope High Setting Register
    [15:0] ADC_DRC_HKN — The slope of the linear, which is determined by the equation that Kn = 1/R. R is the ratio of the linear, which is always an integer. The format is 8.24. (The default value is <1:1>)
  0x288 AC_ADC_DRC_LKN — ADC DRC Linear Slope Low Setting Register
    [15:0] ADC_DRC_LKN — The slope of the linear, which is determined by the equation that Kn = 1/R. R is the ratio of the linear, which is always an integer. The format is 8.24. (The default value is <1:1>)
  0x28C AC_ADC_DRC_SFHAT reset 0x2 — ADC DRC Smooth filter Gain High Attack Time Coef Register
    [10:0] ADC_DRC_SFHAT — The smooth filter attack time parameter setting, which is determined by the equation that AT = 1-exp (-2.2Ts/tr). The format is 3.24. (The default value is 5 ms)
  0x290 AC_ADC_DRC_SFLAT reset 0x5600 — ADC DRC Smooth filter Gain Low Attack Time Coef Register
    [15:0] ADC_DRC_SFLAT — The smooth filter attack time parameter setting, which is determined by the equation that AT = 1-exp (-2.2Ts/tr). The format is 3.24. (The default value is 5 ms)
  0x294 AC_ADC_DRC_SFHRT — ADC DRC Smooth filter Gain High Release Time Coef Register
    [10:0] ADC_DRC_SFHRT — The gain smooth filter release time parameter setting, which is determined by the equation that RT = 1-exp (-2.2Ts/tr). The format is 3.24. (The default value is 200 ms)
  0x298 AC_ADC_DRC_SFLRT reset 0xF04 — ADC DRC Smooth filter Gain Low Release Time Coef Register
    [15:0] ADC_DRC_SFLRT — The gain smooth filter release time parameter setting, which is determined by the equation that RT = 1-exp (-2.2Ts/tr). The format is 3.24. (The default value is 200 ms)
  0x29C AC_ADC_DRC_MXGHS reset 0xFE56 — ADC DRC MAX Gain High Setting Register
    [15:0] ADC_DRC_MXGHS — The max gain setting, which is determined by equation MXG =MXG/6.0206. The format is 8.24 and must -20 dB < MXG < 30 dB (The default value is -10 dB)
  0x2A0 AC_ADC_DRC_MXGLS reset 0xCB0F — ADC DRC MIN Gain Low Setting Register
    [15:0] ADC_DRC_MXGLS — The max gain setting, which is determined by equation MXG =MXG/6.0206. The format is 8.24 and must -20 dB < MXG < 30 dB (The default value is -10 dB)
  0x2A8 AC_ADC_DRC_MNGLS reset 0x2C3F — ADC DRC MIN Gain High Setting Register
    [15:0] ADC_DRC_MNGLS — The min gain setting, which is determined by equation MXG =MNG/6.0206. The format is 8.24 and must -60 dB ≤ MNG ≤ -40 dB (The default value is -40 dB)
  0x2AC AC_ADC_DRC_EPSHC — ADC DRC Expander Smooth Time High Coef Register
    [10:0] ADC_DRC_EPSHC — The gain smooth filter release and attack time parameter setting in expander region, which is determined by the equation that RT = 1-exp (-2.2Ts/tr). The format is 3.24. (The default value is 30 ms)
  0x2B0 AC_ADC_DRC_EPSLC reset 0x640C — ADC DRC Expander Smooth Time Low Coef Register
    [15:0] ADC_DRC_EPSLC — The gain smooth filter release and attack time parameter setting in expander region, which is determined by the equation that RT = 1-exp (-2.2Ts/tr). The format is 3.24. (The default value is 30 ms)
  0x2B8 AC_ADC_DRC_HPFHGAIN reset 0x100 — ADC DRC HPF Gain High Coef Register
    [10:0] ADC_DRC_HPFHGAIN — The gain of HPF coefficient setting, which format is 3.24. (gain = 1)
  0x2BC AC_ADC_DRC_HPFLGAIN — ADC DRC HPF Gain Low Coef Register
    [15:0] ADC_DRC_HPFLGAIN — The gain of HPF coefficient setting, which format is 3.24. (gain = 1)
